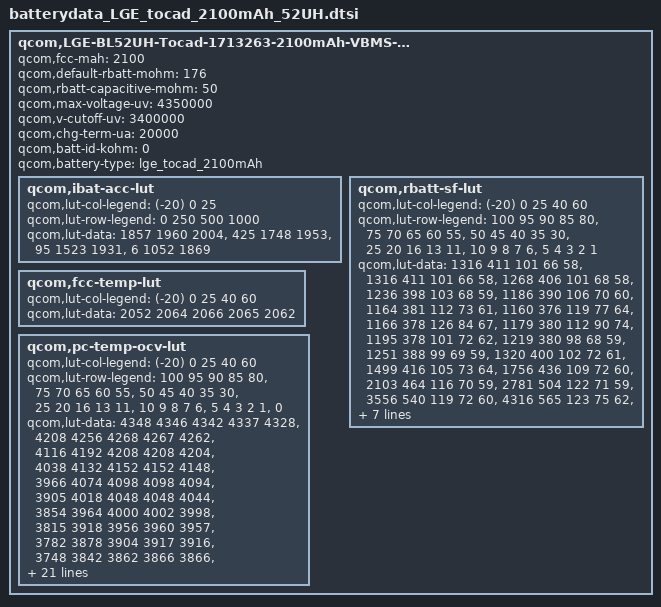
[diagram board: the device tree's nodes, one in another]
 qcom,LGE-BL52UH-Tocad-1713263-2100mAh-VBMS-data {
	qcom,fcc-mah = <2100>;
	qcom,default-rbatt-mohm = <176>;
	qcom,rbatt-capacitive-mohm = <50>;
	qcom,max-voltage-uv = <4350000>;
	qcom,v-cutoff-uv = <3400000>;
	qcom,chg-term-ua = <20000>;
	qcom,batt-id-kohm = <0>;
    qcom,battery-type = "lge_tocad_2100mAh";

	qcom,ibat-acc-lut {
		qcom,lut-col-legend = <(-20) 0 25>;
		qcom,lut-row-legend = <0 250 500 1000>;
		qcom,lut-data = <1857 1960 2004>,
				<425 1748 1953>,
				<95 1523 1931>,
				<6 1052 1869>;
	};

	qcom,rbatt-sf-lut {
		qcom,lut-col-legend = <(-20) 0 25 40 60>;
		qcom,lut-row-legend = <100 95 90 85 80>,
				<75 70 65 60 55>,
				<50 45 40 35 30>,
				<25 20 16 13 11>,
				<10 9 8 7 6>,
				<5 4 3 2 1>;
		qcom,lut-data = <1316 411 101 66 58>,
				<1316 411 101 66 58>,
				<1268 406 101 68 58>,
				<1236 398 103 68 59>,
				<1186 390 106 70 60>,
				<1164 381 112 73 61>,
				<1160 376 119 77 64>,
				<1166 378 126 84 67>,
				<1179 380 112 90 74>,
				<1195 378 101 72 62>,
				<1219 380 98 68 59>,
				<1251 388 99 69 59>,
				<1320 400 102 72 61>,
				<1499 416 105 73 64>,
				<1756 436 109 72 60>,
				<2103 464 116 70 59>,
				<2781 504 122 71 59>,
				<3556 540 119 72 60>,
				<4316 565 123 75 62>,
				<4992 576 132 79 65>,
				<5438 572 140 83 66>,
				<5877 553 143 85 66>,
				<6083 530 146 86 67>,
				<6848 539 147 89 72>,
				<7939 553 147 96 77>,
				<9403 579 149 102 83>,
				<11370 621 155 109 88>,
				<14213 709 169 117 94>,
				<18456 1040 200 134 106>,
				<25234 2080 353 219 173>;
	};

	qcom,fcc-temp-lut {
		qcom,lut-col-legend = <(-20) 0 25 40 60>;
		qcom,lut-data = <2052 2064 2066 2065 2062>;
	};

	qcom,pc-temp-ocv-lut {
		qcom,lut-col-legend = <(-20) 0 25 40 60>;
		qcom,lut-row-legend = <100 95 90 85 80>,
				<75 70 65 60 55>,
				<50 45 40 35 30>,
				<25 20 16 13 11>,
				<10 9 8 7 6>,
				<5 4 3 2 1>,
				<0>;
		qcom,lut-data = <4348 4346 4342 4337 4328>,
				<4208 4256 4268 4267 4262>,
				<4116 4192 4208 4208 4204>,
				<4038 4132 4152 4152 4148>,
				<3966 4074 4098 4098 4094>,
				<3905 4018 4048 4048 4044>,
				<3854 3964 4000 4002 3998>,
				<3815 3918 3956 3960 3957>,
				<3782 3878 3904 3917 3916>,
				<3748 3842 3862 3866 3866>,
				<3716 3812 3830 3834 3833>,
				<3684 3787 3806 3810 3810>,
				<3655 3768 3788 3792 3791>,
				<3627 3750 3773 3776 3776>,
				<3597 3730 3760 3760 3752>,
				<3562 3708 3744 3742 3730>,
				<3522 3682 3717 3715 3703>,
				<3484 3654 3688 3687 3677>,
				<3449 3625 3670 3672 3664>,
				<3423 3600 3660 3666 3658>,
				<3408 3582 3653 3660 3653>,
				<3393 3564 3644 3652 3644>,
				<3377 3540 3630 3636 3624>,
				<3356 3510 3601 3607 3591>,
				<3334 3471 3560 3568 3550>,
				<3308 3424 3508 3520 3502>,
				<3274 3368 3444 3460 3443>,
				<3232 3300 3370 3388 3372>,
				<3174 3214 3282 3296 3282>,
				<3092 3118 3168 3168 3153>,
				<3000 3000 3000 3000 3000>;
	};
};
